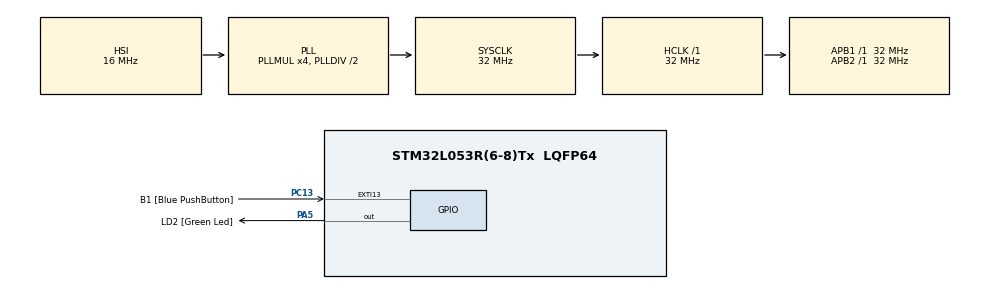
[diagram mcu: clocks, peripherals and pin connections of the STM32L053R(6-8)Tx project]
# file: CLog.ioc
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Mcu.Family=STM32L0
Mcu.Name=STM32L053R(6-8)Tx
Mcu.Package=LQFP64
PA13.GPIO_Label=TMS
PA13.Mode=Serial_Wire
PA13.Signal=SYS_SWDIO
PA14.GPIO_Label=TCK
PA14.Mode=Serial_Wire
PA14.Signal=SYS_SWCLK
PA2.GPIO_Label=USART_TX
PA2.Signal=USART2_TX
PA3.GPIO_Label=USART_RX
PA3.Signal=USART2_RX
PA5.GPIO_Label=LD2 [Green Led]
PA5.Signal=GPIO_Output
PC13.GPIO_Label=B1 [Blue PushButton]
PC13.GPIO_ModeDefaultEXTI=GPIO_MODE_IT_FALLING
PC13.Signal=GPXTI13
PC14-OSC32_IN.Signal=RCC_OSC32_IN
PC15-OSC32_OUT.Signal=RCC_OSC32_OUT
PH0-OSC_IN.Signal=RCC_OSC_IN
PH1-OSC_OUT.Signal=RCC_OSC_OUT
ProjectManager.HeapSize=0x200
ProjectManager.StackSize=0x400
ProjectManager.TargetToolchain=EWARM V8.32
RCC.AHBFreq_Value=32000000
RCC.APB1Freq_Value=32000000
RCC.APB1TimFreq_Value=32000000
RCC.APB2Freq_Value=32000000
RCC.APB2TimFreq_Value=32000000
RCC.HCLKFreq_Value=32000000
RCC.HSE_VALUE=8000000
RCC.HSI16_VALUE=16000000
RCC.HSI48_VALUE=48000000
RCC.HSI_VALUE=16000000
RCC.LSEState=RCC_LSE_ON
RCC.LSE_VALUE=32768
RCC.MSI_VALUE=2097000
RCC.PLLMUL=RCC_PLLMUL_4
RCC.SYSCLKFreq_VALUE=32000000
RCC.SYSCLKSource=RCC_SYSCLKSOURCE_PLLCLK
RCC.VCOOutputFreq_Value=64000000
board=NUCLEO-L053R8

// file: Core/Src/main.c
/* USER CODE BEGIN Header */
/**
 ******************************************************************************
 * @file           : main.c
 * @brief          : Main program body
 ******************************************************************************
 * @attention
 *
 * <h2><center>&copy; Copyright (c) 2020 STMicroelectronics.
 * All rights reserved.</center></h2>
 *
 * This software component is licensed by ST under BSD 3-Clause license,
 * the "License"; You may not use this file except in compliance with the
 * License. You may obtain a copy of the License at:
 *                        opensource.org/licenses/BSD-3-Clause
 *
 ******************************************************************************
 */
 /* USER CODE END Header */
 /* Includes ------------------------------------------------------------------*/
#include "main.h"

/* USER CODE BEGIN Includes */
#include "dlog.h"
#include <stdio.h>
#include <string.h>
/* USER CODE END Includes */

void SystemClock_Config(void);
static void MX_GPIO_Init(void);
/* USER CODE BEGIN PFP */
static DLOG_TIMESTAMP_T DLogTimestamp(void);
static void DLogStorage(DLOG_HEAD_T * head, uint8_t * body, size_t size);
/* USER CODE END PFP */

/* USER CODE BEGIN 0 */
static FILE * fp = NULL;
/* USER CODE END 0 */

int main(void)
{

    /* MCU Configuration--------------------------------------------------------*/

    /* Reset of all peripherals, Initializes the Flash interface and the Systick. */
    HAL_Init();

    /* Configure the system clock */
    SystemClock_Config();

    /* USER CODE BEGIN SysInit */
    fp = fopen("log.bin", "w+");
    /* USER CODE END SysInit */

    /* Initialize all configured peripherals */
    MX_GPIO_Init();
    /* USER CODE BEGIN 2 */
    DLogInit(DLogTimestamp, DLogStorage);
    DLogPrintfError("DLog_00:no arguments.");
    HAL_Delay(1);
    DLogPrintfWarn("DLog_01:int = %d.", 1);
    HAL_Delay(2);
    DLogPrintfInfo("DLog_02:float = %f.", 2.0f);
    HAL_Delay(3);
    DLogPrintfDebug("DLog_03:hex = %x.", 0xaf);
    HAL_Delay(3);
    DLogPrintfError("DLog_04:char = %c.", 'a');
    HAL_Delay(4);
    DLogPrintfError("DLog_05:a = %d, b = %d.", 4, 5);
    HAL_Delay(5);
    fclose(fp);
    /* USER CODE END 2 */

    /* Infinite loop */
    while (1) {

    }
}

void SystemClock_Config(void)
{
    RCC_OscInitTypeDef RCC_OscInitStruct = { 0 };
    RCC_ClkInitTypeDef RCC_ClkInitStruct = { 0 };

    /** Configure the main internal regulator output voltage
    */
    __HAL_PWR_VOLTAGESCALING_CONFIG(PWR_REGULATOR_VOLTAGE_SCALE1);

    /** Initializes the RCC Oscillators according to the specified parameters
    * in the RCC_OscInitTypeDef structure.
    */
    RCC_OscInitStruct.OscillatorType = RCC_OSCILLATORTYPE_HSI;
    RCC_OscInitStruct.HSIState = RCC_HSI_ON;
    RCC_OscInitStruct.HSICalibrationValue = RCC_HSICALIBRATION_DEFAULT;
    RCC_OscInitStruct.PLL.PLLState = RCC_PLL_ON;
    RCC_OscInitStruct.PLL.PLLSource = RCC_PLLSOURCE_HSI;
    RCC_OscInitStruct.PLL.PLLMUL = RCC_PLLMUL_4;
    RCC_OscInitStruct.PLL.PLLDIV = RCC_PLLDIV_2;
    if (HAL_RCC_OscConfig(&RCC_OscInitStruct) != HAL_OK) {
        Error_Handler();
    }

    /** Initializes the CPU, AHB and APB buses clocks
    */
    RCC_ClkInitStruct.ClockType = RCC_CLOCKTYPE_HCLK | RCC_CLOCKTYPE_SYSCLK
        | RCC_CLOCKTYPE_PCLK1 | RCC_CLOCKTYPE_PCLK2;
    RCC_ClkInitStruct.SYSCLKSource = RCC_SYSCLKSOURCE_PLLCLK;
    RCC_ClkInitStruct.AHBCLKDivider = RCC_SYSCLK_DIV1;
    RCC_ClkInitStruct.APB1CLKDivider = RCC_HCLK_DIV1;
    RCC_ClkInitStruct.APB2CLKDivider = RCC_HCLK_DIV1;

    if (HAL_RCC_ClockConfig(&RCC_ClkInitStruct, FLASH_LATENCY_1) != HAL_OK) {
        Error_Handler();
    }
}

static void MX_GPIO_Init(void)
{
    GPIO_InitTypeDef GPIO_InitStruct = { 0 };

    /* GPIO Ports Clock Enable */
    __HAL_RCC_GPIOC_CLK_ENABLE();
    __HAL_RCC_GPIOH_CLK_ENABLE();
    __HAL_RCC_GPIOA_CLK_ENABLE();

    /*Configure GPIO pin Output Level */
    HAL_GPIO_WritePin(LD2_GPIO_Port, LD2_Pin, GPIO_PIN_RESET);

    /*Configure GPIO pin : B1_Pin */
    GPIO_InitStruct.Pin = B1_Pin;
    GPIO_InitStruct.Mode = GPIO_MODE_IT_FALLING;
    GPIO_InitStruct.Pull = GPIO_NOPULL;
    HAL_GPIO_Init(B1_GPIO_Port, &GPIO_InitStruct);

    /*Configure GPIO pins : USART_TX_Pin USART_RX_Pin */
    GPIO_InitStruct.Pin = USART_TX_Pin | USART_RX_Pin;
    GPIO_InitStruct.Mode = GPIO_MODE_AF_PP;
    GPIO_InitStruct.Pull = GPIO_NOPULL;
    GPIO_InitStruct.Speed = GPIO_SPEED_FREQ_VERY_HIGH;
    GPIO_InitStruct.Alternate = GPIO_AF4_USART2;
    HAL_GPIO_Init(GPIOA, &GPIO_InitStruct);

    /*Configure GPIO pin : LD2_Pin */
    GPIO_InitStruct.Pin = LD2_Pin;
    GPIO_InitStruct.Mode = GPIO_MODE_OUTPUT_PP;
    GPIO_InitStruct.Pull = GPIO_NOPULL;
    GPIO_InitStruct.Speed = GPIO_SPEED_FREQ_LOW;
    HAL_GPIO_Init(LD2_GPIO_Port, &GPIO_InitStruct);

}

/* USER CODE BEGIN 4 */
static unsigned int DLogTimestamp(void) { return HAL_GetTick(); }

static void DLogStorage(DLOG_HEAD_T * head, uint8_t * body, size_t size)
{
    static DLOG_HEAD_T sn = { 0 };
    sn.SN = sn.SN + 1;
    head->SN = sn.SN;
    fwrite(head, sizeof(DLOG_HEAD_T), 1, fp);
    fwrite(body, 1, size, fp);
}
/* USER CODE END 4 */

void Error_Handler(void)
{
}
